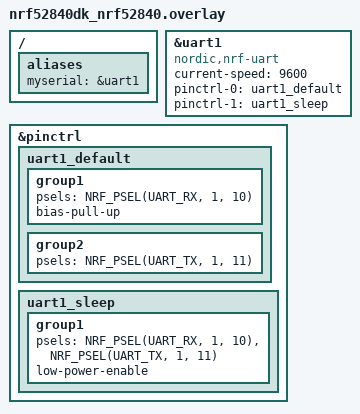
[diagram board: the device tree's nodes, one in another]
// To get started, press Ctrl+Space to bring up the completion menu and view the available nodes.

// You can also use the buttons in the sidebar to perform actions on nodes.
// Actions currently available include:

// * Enabling / disabling the node
// * Adding the bus to a bus
// * Removing the node
// * Connecting ADC channels

// For more help, browse the DeviceTree documentation at https://docs.zephyrproject.org/latest/guides/dts/index.html
// You can also visit the nRF DeviceTree extension documentation at https://nrfconnect.github.io/vscode-nrf-connect/devicetree/nrfdevicetree.html

/ {
    aliases {
        myserial = &uart1;
    };
};

// &uart0 {
//     status = "disabled";
// };

arduino_serial: &uart1 {
    status = "okay";
    compatible = "nordic,nrf-uart";
	current-speed = <9600>;
	pinctrl-0 = <&uart1_default>;
	pinctrl-1 = <&uart1_sleep>;
	pinctrl-names = "default", "sleep";
};

&pinctrl {
	uart1_default: uart1_default {
		group1 {
			psels = <NRF_PSEL(UART_RX, 1, 10)>;
			bias-pull-up;
		};
		group2 {
			psels = <NRF_PSEL(UART_TX, 1, 11)>;
		};
	};

	uart1_sleep: uart1_sleep {
		group1 {
			psels = <NRF_PSEL(UART_RX, 1, 10)>,
				<NRF_PSEL(UART_TX, 1, 11)>;
			low-power-enable;
		};
	};
};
